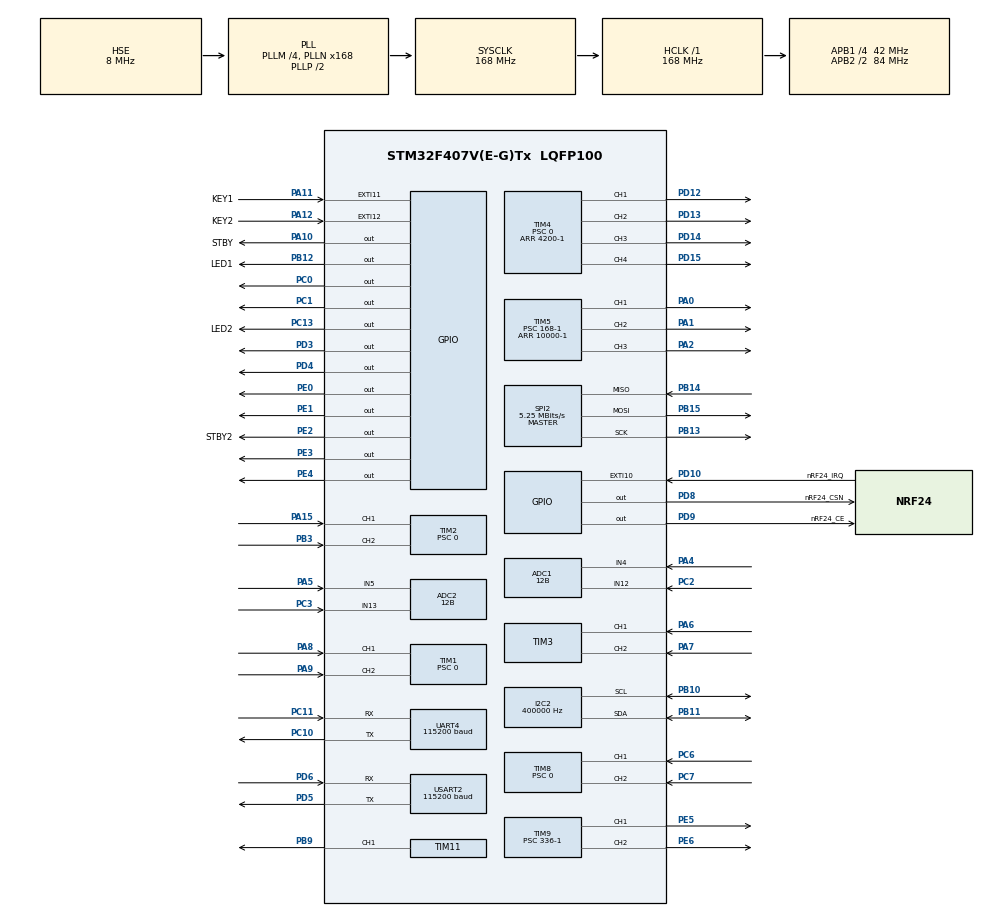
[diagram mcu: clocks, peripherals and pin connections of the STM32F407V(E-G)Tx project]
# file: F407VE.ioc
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ADC1.Channel-0\#ChannelRegularConversion=ADC_CHANNEL_4
ADC1.Channel-1\#ChannelRegularConversion=ADC_CHANNEL_12
ADC1.Channel-IN12=ADC_CHANNEL_12
ADC1.Channel-IN4=ADC_CHANNEL_4
ADC1.ClockPrescaler=ADC_CLOCK_SYNC_PCLK_DIV4
ADC1.ContinuousConvMode=ENABLE
ADC1.DMAContinuousRequests=ENABLE
ADC1.DataAlign=ADC_DATAALIGN_RIGHT
ADC1.DiscontinuousConvMode=DISABLE
ADC1.EOCSelection=ADC_EOC_SINGLE_CONV
ADC1.EnableAnalogWatchDog=false
ADC1.ExternalTrigConv=ADC_SOFTWARE_START
ADC1.ExternalTrigConvEdge=ADC_EXTERNALTRIGCONVEDGE_NONE
ADC1.Mode=ADC_DUALMODE_REGSIMULT
ADC1.NbrOfConversion=2
ADC1.Rank-0\#ChannelRegularConversion=1
ADC1.Rank-1\#ChannelRegularConversion=2
ADC1.Resolution=ADC_RESOLUTION_12B
ADC1.SamplingTime-0\#ChannelRegularConversion=ADC_SAMPLETIME_84CYCLES
ADC1.SamplingTime-1\#ChannelRegularConversion=ADC_SAMPLETIME_84CYCLES
ADC1.ScanConvMode=ENABLE
ADC1.master=1
ADC2.Channel-2\#ChannelRegularConversion=ADC_CHANNEL_5
ADC2.Channel-3\#ChannelRegularConversion=ADC_CHANNEL_13
ADC2.Channel-IN13=ADC_CHANNEL_13
ADC2.Channel-IN5=ADC_CHANNEL_5
ADC2.ClockPrescaler=ADC_CLOCK_SYNC_PCLK_DIV4
ADC2.ContinuousConvMode=ENABLE
ADC2.DMAAccessMode=ADC_DMAACCESSMODE_2
ADC2.DMAContinuousRequests=DISABLE
ADC2.DataAlign=ADC_DATAALIGN_RIGHT
ADC2.DiscontinuousConvMode=DISABLE
ADC2.EOCSelection=ADC_EOC_SINGLE_CONV
ADC2.EnableAnalogWatchDog=false
ADC2.Mode=ADC_DUALMODE_REGSIMULT
ADC2.NbrOfConversion=2
ADC2.Rank-2\#ChannelRegularConversion=1
ADC2.Rank-3\#ChannelRegularConversion=2
ADC2.Resolution=ADC_RESOLUTION_12B
ADC2.SamplingTime-2\#ChannelRegularConversion=ADC_SAMPLETIME_84CYCLES
ADC2.SamplingTime-3\#ChannelRegularConversion=ADC_SAMPLETIME_84CYCLES
ADC2.ScanConvMode=ENABLE
Dma.ADC1.0.Direction=DMA_PERIPH_TO_MEMORY
Dma.ADC1.0.FIFOMode=DMA_FIFOMODE_DISABLE
Dma.ADC1.0.Instance=DMA2_Stream0
Dma.ADC1.0.MemDataAlignment=DMA_MDATAALIGN_WORD
Dma.ADC1.0.MemInc=DMA_MINC_ENABLE
Dma.ADC1.0.Mode=DMA_CIRCULAR
Dma.ADC1.0.PeriphDataAlignment=DMA_PDATAALIGN_WORD
Dma.ADC1.0.PeriphInc=DMA_PINC_DISABLE
Dma.ADC1.0.Priority=DMA_PRIORITY_LOW
Dma.Request0=ADC1
FREERTOS.HEAP_NUMBER=4
FREERTOS.INCLUDE_eTaskGetState=0
FREERTOS.INCLUDE_pcTaskGetTaskName=0
FREERTOS.INCLUDE_uxTaskGetStackHighWaterMark=1
FREERTOS.INCLUDE_uxTaskGetStackHighWaterMark2=0
FREERTOS.INCLUDE_uxTaskPriorityGet=1
FREERTOS.INCLUDE_vTaskCleanUpResources=0
FREERTOS.INCLUDE_vTaskDelay=1
FREERTOS.INCLUDE_vTaskDelayUntil=1
FREERTOS.INCLUDE_vTaskDelete=1
FREERTOS.INCLUDE_vTaskPrioritySet=1
FREERTOS.INCLUDE_vTaskSuspend=1
FREERTOS.INCLUDE_xEventGroupSetBitFromISR=0
FREERTOS.INCLUDE_xQueueGetMutexHolder=0
FREERTOS.INCLUDE_xSemaphoreGetMutexHolder=0
FREERTOS.INCLUDE_xTaskAbortDelay=0
FREERTOS.INCLUDE_xTaskGetCurrentTaskHandle=0
FREERTOS.INCLUDE_xTaskGetHandle=0
FREERTOS.INCLUDE_xTaskResumeFromISR=1
FREERTOS.MEMORY_ALLOCATION=2
FREERTOS.Tasks01=App_Remote_Task,2,512,StartApp_Remote_Task,As weak,NULL,Dynamic,NULL,NULL;App_ChassisTask,1,1024,StartApp_Chassis_Task,As weak,NULL,Dynamic,NULL,NULL;App_Grab_Task,0,768,StartApp_Grab_Task,As weak,NULL,Dynamic,NULL,NULL;App_Sense_Task,-1,512,StartApp_Sense_Task,As weak,NULL,Dynamic,NULL,NULL;App_Daemon_Task,-2,768,StartApp_Daemon_Task,As weak,NULL,Dynamic,NULL,NULL;App_TestBench_T,0,512,StartApp_TestBench_Task,As weak,NULL,Dynamic,NULL,NULL
FREERTOS.configCHECK_FOR_STACK_OVERFLOW=0
FREERTOS.configENABLE_BACKWARD_COMPATIBILITY=1
FREERTOS.configENABLE_FPU=0
FREERTOS.configGENERATE_RUN_TIME_STATS=0
FREERTOS.configIDLE_SHOULD_YIELD=1
FREERTOS.configLIBRARY_LOWEST_INTERRUPT_PRIORITY=15
FREERTOS.configLIBRARY_MAX_SYSCALL_INTERRUPT_PRIORITY=5
FREERTOS.configMAX_CO_ROUTINE_PRIORITIES=2
FREERTOS.configMAX_PRIORITIES=7
FREERTOS.configMAX_TASK_NAME_LEN=16
FREERTOS.configMINIMAL_STACK_SIZE=128
FREERTOS.configQUEUE_REGISTRY_SIZE=8
FREERTOS.configRECORD_STACK_HIGH_ADDRESS=0
FREERTOS.configTICK_RATE_HZ=1000
FREERTOS.configTOTAL_HEAP_SIZE=20480
FREERTOS.configUSE_APPLICATION_TASK_TAG=0
FREERTOS.configUSE_COUNTING_SEMAPHORES=0
FREERTOS.configUSE_CO_ROUTINES=0
FREERTOS.configUSE_DAEMON_TASK_STARTUP_HOOK=0
FREERTOS.configUSE_IDLE_HOOK=0
FREERTOS.configUSE_MALLOC_FAILED_HOOK=0
FREERTOS.configUSE_MUTEXES=1
FREERTOS.configUSE_NEWLIB_REENTRANT=0
FREERTOS.configUSE_POSIX_ERRNO=0
FREERTOS.configUSE_PREEMPTION=1
FREERTOS.configUSE_RECURSIVE_MUTEXES=0
FREERTOS.configUSE_STATS_FORMATTING_FUNCTIONS=0
FREERTOS.configUSE_TASK_NOTIFICATIONS=1
FREERTOS.configUSE_TICKLESS_IDLE=0
FREERTOS.configUSE_TICK_HOOK=0
FREERTOS.configUSE_TIMERS=0
FREERTOS.configUSE_TRACE_FACILITY=0
FREERTOS.copyHeapFile=1
I2C2.AddressingMode=I2C_ADDRESSINGMODE_7BIT
I2C2.ClockSpeed=400000
I2C2.DualAddressMode=I2C_DUALADDRESS_DISABLE
I2C2.DutyCycle=I2C_DUTYCYCLE_2
I2C2.GeneralCallMode=I2C_GENERALCALL_DISABLE
I2C2.I2C_Mode=I2C_Fast
I2C2.NoStretchMode=I2C_NOSTRETCH_DISABLE
I2C2.OwnAddress=0
Mcu.Family=STM32F4
Mcu.Name=STM32F407V(E-G)Tx
Mcu.Package=LQFP100
NVIC.DMA2_Stream0_IRQn=true\:5\:0\:false\:false\:true\:true\:false\:true\:true
NVIC.EXTI15_10_IRQn=true\:5\:0\:false\:false\:true\:true\:true\:true\:true
NVIC.PriorityGroup=NVIC_PRIORITYGROUP_4
NVIC.TIM6_DAC_IRQn=true\:15\:0\:false\:false\:true\:false\:true\:true\:true
NVIC.TimeBase=TIM6_DAC_IRQn
NVIC.TimeBaseIP=TIM6
NVIC.UART4_IRQn=true\:5\:0\:false\:false\:true\:true\:true\:true\:true
NVIC.USART2_IRQn=true\:5\:0\:false\:false\:true\:true\:true\:true\:true
PA0-WKUP.Signal=S_TIM5_CH1
PA1.Signal=S_TIM5_CH2
PA10.GPIO_Label=STBY
PA10.Signal=GPIO_Output
PA11.GPIO_Label=KEY1
PA11.GPIO_ModeDefaultEXTI=GPIO_MODE_IT_FALLING
PA11.GPIO_PuPd=GPIO_PULLUP
PA11.Signal=GPXTI11
PA12.GPIO_Label=KEY2
PA12.GPIO_ModeDefaultEXTI=GPIO_MODE_IT_FALLING
PA12.GPIO_PuPd=GPIO_PULLUP
PA12.Signal=GPXTI12
PA13.Mode=Serial_Wire
PA13.Signal=SYS_JTMS-SWDIO
PA14.Mode=Serial_Wire
PA14.Signal=SYS_JTCK-SWCLK
PA15.Signal=S_TIM2_CH1_ETR
PA2.Signal=S_TIM5_CH3
PA4.Signal=ADCx_IN4
PA5.Signal=ADCx_IN5
PA6.Signal=S_TIM3_CH1
PA7.Signal=S_TIM3_CH2
PA8.Signal=S_TIM1_CH1
PA9.Signal=S_TIM1_CH2
PB10.Mode=I2C
PB10.Signal=I2C2_SCL
PB11.Mode=I2C
PB11.Signal=I2C2_SDA
PB12.GPIO_Label=LED1
PB12.Signal=GPIO_Output
PB13.Mode=Full_Duplex_Master
PB13.Signal=SPI2_SCK
PB14.Mode=Full_Duplex_Master
PB14.Signal=SPI2_MISO
PB15.Mode=Full_Duplex_Master
PB15.Signal=SPI2_MOSI
PB3.Signal=S_TIM2_CH2
PB9.Signal=S_TIM11_CH1
PC0.Signal=GPIO_Output
PC1.Signal=GPIO_Output
PC10.Mode=Asynchronous
PC10.Signal=UART4_TX
PC11.Mode=Asynchronous
PC11.Signal=UART4_RX
PC13-ANTI_TAMP.GPIO_Label=LED2
PC13-ANTI_TAMP.Signal=GPIO_Output
PC14-OSC32_IN.Mode=LSE-External-Oscillator
PC14-OSC32_IN.Signal=RCC_OSC32_IN
PC15-OSC32_OUT.Mode=LSE-External-Oscillator
PC15-OSC32_OUT.Signal=RCC_OSC32_OUT
PC2.Signal=ADCx_IN12
PC3.Signal=ADCx_IN13
PC6.Signal=S_TIM8_CH1
PC7.Signal=S_TIM8_CH2
PD10.GPIO_Label=nRF24_IRQ
PD10.GPIO_ModeDefaultEXTI=GPIO_MODE_IT_FALLING
PD10.GPIO_PuPd=GPIO_PULLUP
PD10.Signal=GPXTI10
PD12.Signal=S_TIM4_CH1
PD13.Signal=S_TIM4_CH2
PD14.Signal=S_TIM4_CH3
PD15.Signal=S_TIM4_CH4
PD3.Signal=GPIO_Output
PD4.Signal=GPIO_Output
PD5.Mode=Asynchronous
PD5.Signal=USART2_TX
PD6.Mode=Asynchronous
PD6.Signal=USART2_RX
PD8.GPIO_Label=nRF24_CSN
PD8.Signal=GPIO_Output
PD9.GPIO_Label=nRF24_CE
PD9.Signal=GPIO_Output
PE0.Signal=GPIO_Output
PE1.Signal=GPIO_Output
PE2.GPIO_Label=STBY2
PE2.Signal=GPIO_Output
PE3.Signal=GPIO_Output
PE4.Signal=GPIO_Output
PE5.Signal=S_TIM9_CH1
PE6.Signal=S_TIM9_CH2
PH0-OSC_IN.Mode=HSE-External-Oscillator
PH0-OSC_IN.Signal=RCC_OSC_IN
PH1-OSC_OUT.Mode=HSE-External-Oscillator
PH1-OSC_OUT.Signal=RCC_OSC_OUT
ProjectManager.HeapSize=0x200
ProjectManager.StackSize=0x400
ProjectManager.TargetToolchain=CMake
RCC.48MHZClocksFreq_Value=84000000
RCC.AHBFreq_Value=168000000
RCC.APB1CLKDivider=RCC_HCLK_DIV4
RCC.APB1Freq_Value=42000000
RCC.APB1TimFreq_Value=84000000
RCC.APB2CLKDivider=RCC_HCLK_DIV2
RCC.APB2Freq_Value=84000000
RCC.APB2TimFreq_Value=168000000
RCC.CortexFreq_Value=168000000
RCC.FLatency=FLASH_LATENCY_5
RCC.HCLKFreq_Value=168000000
RCC.HSE_VALUE=8000000
RCC.HSI_VALUE=16000000
RCC.PLLM=4
RCC.PLLN=168
RCC.PLLSourceVirtual=RCC_PLLSOURCE_HSE
RCC.SYSCLKFreq_VALUE=168000000
RCC.SYSCLKSource=RCC_SYSCLKSOURCE_PLLCLK
RCC.VCOOutputFreq_Value=336000000
SH.ADCx_IN12.0=ADC1_IN12,IN12
SH.ADCx_IN13.0=ADC2_IN13,IN13
SH.ADCx_IN4.0=ADC1_IN4,IN4
SH.ADCx_IN5.0=ADC2_IN5,IN5
SH.S_TIM11_CH1.0=TIM11_CH1,PWM Generation1 CH1
SH.S_TIM1_CH1.0=TIM1_CH1,Encoder_Interface
SH.S_TIM1_CH2.0=TIM1_CH2,Encoder_Interface
SH.S_TIM2_CH1_ETR.0=TIM2_CH1,Encoder_Interface
SH.S_TIM2_CH2.0=TIM2_CH2,Encoder_Interface
SH.S_TIM3_CH1.0=TIM3_CH1,Encoder_Interface
SH.S_TIM3_CH2.0=TIM3_CH2,Encoder_Interface
SH.S_TIM4_CH1.0=TIM4_CH1,PWM Generation1 CH1
SH.S_TIM4_CH2.0=TIM4_CH2,PWM Generation2 CH2
SH.S_TIM4_CH3.0=TIM4_CH3,PWM Generation3 CH3
SH.S_TIM4_CH4.0=TIM4_CH4,PWM Generation4 CH4
SH.S_TIM5_CH1.0=TIM5_CH1,PWM Generation1 CH1
SH.S_TIM5_CH2.0=TIM5_CH2,PWM Generation2 CH2
SH.S_TIM5_CH3.0=TIM5_CH3,PWM Generation3 CH3
SH.S_TIM8_CH1.0=TIM8_CH1,Encoder_Interface
SH.S_TIM8_CH2.0=TIM8_CH2,Encoder_Interface
SH.S_TIM9_CH1.0=TIM9_CH1,PWM Generation1 CH1
SH.S_TIM9_CH2.0=TIM9_CH2,PWM Generation2 CH2
SPI2.BaudRatePrescaler=SPI_BAUDRATEPRESCALER_8
SPI2.CLKPhase=SPI_PHASE_1EDGE
SPI2.CLKPolarity=SPI_POLARITY_LOW
SPI2.CRCCalculation=SPI_CRCCALCULATION_DISABLE
SPI2.CalculateBaudRate=5.25 MBits/s
SPI2.DataSize=SPI_DATASIZE_8BIT
SPI2.Direction=SPI_DIRECTION_2LINES
SPI2.FirstBit=SPI_FIRSTBIT_MSB
SPI2.Mode=SPI_MODE_MASTER
SPI2.NSS=SPI_NSS_SOFT
SPI2.TIMode=SPI_TIMODE_DISABLE
SPI2.VirtualType=VM_MASTER
TIM1.AutoReloadPreload=TIM_AUTORELOAD_PRELOAD_DISABLE
TIM1.ClockDivision=TIM_CLOCKDIVISION_DIV1
TIM1.CounterMode=TIM_COUNTERMODE_UP
TIM1.EncoderMode=TIM_ENCODERMODE_TI12
TIM1.IC1Filter=5
TIM1.IC1Polarity=TIM_ICPOLARITY_RISING
TIM1.IC1Prescaler=TIM_ICPSC_DIV1
TIM1.IC1Selection=TIM_ICSELECTION_DIRECTTI
TIM1.IC2Filter=5
TIM1.IC2Polarity=TIM_ICPOLARITY_RISING
TIM1.IC2Prescaler=TIM_ICPSC_DIV1
TIM1.IC2Selection=TIM_ICSELECTION_DIRECTTI
TIM1.Period=65535
TIM1.Prescaler=0
TIM1.RepetitionCounter=0
TIM1.TIM_MasterOutputTrigger=TIM_TRGO_RESET
TIM1.TIM_MasterSlaveMode=TIM_MASTERSLAVEMODE_DISABLE
TIM10.Channel=TIM_CHANNEL_1
TIM11.Channel=TIM_CHANNEL_1
TIM2.AutoReloadPreload=TIM_AUTORELOAD_PRELOAD_DISABLE
TIM2.ClockDivision=TIM_CLOCKDIVISION_DIV1
TIM2.CounterMode=TIM_COUNTERMODE_UP
TIM2.EncoderMode=TIM_ENCODERMODE_TI12
TIM2.IC1Filter=5
TIM2.IC1Polarity=TIM_ICPOLARITY_RISING
TIM2.IC1Prescaler=TIM_ICPSC_DIV1
TIM2.IC1Selection=TIM_ICSELECTION_DIRECTTI
TIM2.IC2Filter=5
TIM2.IC2Polarity=TIM_ICPOLARITY_RISING
TIM2.IC2Prescaler=TIM_ICPSC_DIV1
TIM2.IC2Selection=TIM_ICSELECTION_DIRECTTI
TIM2.Period=65535
TIM2.Prescaler=0
TIM2.TIM_MasterOutputTrigger=TIM_TRGO_RESET
TIM2.TIM_MasterSlaveMode=TIM_MASTERSLAVEMODE_DISABLE
TIM3.EncoderMode=TIM_ENCODERMODE_TI12
TIM3.IC1Filter=5
TIM3.IC2Filter=5
TIM4.AutoReloadPreload=TIM_AUTORELOAD_PRELOAD_DISABLE
TIM4.Channel-PWM\ Generation1\ CH1=TIM_CHANNEL_1
TIM4.Channel-PWM\ Generation2\ CH2=TIM_CHANNEL_2
TIM4.Channel-PWM\ Generation3\ CH3=TIM_CHANNEL_3
TIM4.Channel-PWM\ Generation4\ CH4=TIM_CHANNEL_4
TIM4.ClockDivision=TIM_CLOCKDIVISION_DIV1
TIM4.CounterMode=TIM_COUNTERMODE_UP
TIM4.OC1Preload_PWM=ENABLE
TIM4.OC2Preload_PWM=ENABLE
TIM4.OC3Preload_PWM=ENABLE
TIM4.OCFastMode_PWM-PWM\ Generation1\ CH1=TIM_OCFAST_DISABLE
TIM4.OCFastMode_PWM-PWM\ Generation2\ CH2=TIM_OCFAST_DISABLE
TIM4.OCFastMode_PWM-PWM\ Generation3\ CH3=TIM_OCFAST_DISABLE
TIM4.OCMode_PWM-PWM\ Generation1\ CH1=TIM_OCMODE_PWM1
TIM4.OCMode_PWM-PWM\ Generation2\ CH2=TIM_OCMODE_PWM1
TIM4.OCMode_PWM-PWM\ Generation3\ CH3=TIM_OCMODE_PWM1
TIM4.OCPolarity_1=TIM_OCPOLARITY_HIGH
TIM4.OCPolarity_2=TIM_OCPOLARITY_HIGH
TIM4.OCPolarity_3=TIM_OCPOLARITY_HIGH
TIM4.Period=4200-1
TIM4.Prescaler=0
TIM4.Pulse-PWM\ Generation1\ CH1=0
TIM4.Pulse-PWM\ Generation2\ CH2=0
TIM4.Pulse-PWM\ Generation3\ CH3=0
TIM4.TIM_MasterOutputTrigger=TIM_TRGO_RESET
TIM4.TIM_MasterSlaveMode=TIM_MASTERSLAVEMODE_DISABLE
TIM5.AutoReloadPreload=TIM_AUTORELOAD_PRELOAD_DISABLE
TIM5.Channel-PWM\ Generation1\ CH1=TIM_CHANNEL_1
TIM5.Channel-PWM\ Generation2\ CH2=TIM_CHANNEL_2
TIM5.Channel-PWM\ Generation3\ CH3=TIM_CHANNEL_3
TIM5.ClockDivision=TIM_CLOCKDIVISION_DIV1
TIM5.CounterMode=TIM_COUNTERMODE_UP
TIM5.OC1Preload_PWM=ENABLE
TIM5.OC2Preload_PWM=ENABLE
TIM5.OC3Preload_PWM=ENABLE
TIM5.OCFastMode_PWM-PWM\ Generation1\ CH1=TIM_OCFAST_DISABLE
TIM5.OCFastMode_PWM-PWM\ Generation2\ CH2=TIM_OCFAST_DISABLE
TIM5.OCFastMode_PWM-PWM\ Generation3\ CH3=TIM_OCFAST_DISABLE
TIM5.OCMode_PWM-PWM\ Generation1\ CH1=TIM_OCMODE_PWM1
TIM5.OCMode_PWM-PWM\ Generation2\ CH2=TIM_OCMODE_PWM1
TIM5.OCMode_PWM-PWM\ Generation3\ CH3=TIM_OCMODE_PWM1
TIM5.OCPolarity_1=TIM_OCPOLARITY_HIGH
TIM5.OCPolarity_2=TIM_OCPOLARITY_HIGH
TIM5.OCPolarity_3=TIM_OCPOLARITY_HIGH
TIM5.Period=10000-1
TIM5.Prescaler=168-1
TIM5.Pulse-PWM\ Generation1\ CH1=0
TIM5.Pulse-PWM\ Generation2\ CH2=0
TIM5.Pulse-PWM\ Generation3\ CH3=0
TIM5.TIM_MasterOutputTrigger=TIM_TRGO_RESET
TIM5.TIM_MasterSlaveMode=TIM_MASTERSLAVEMODE_DISABLE
TIM8.AutoReloadPreload=TIM_AUTORELOAD_PRELOAD_DISABLE
TIM8.ClockDivision=TIM_CLOCKDIVISION_DIV1
TIM8.CounterMode=TIM_COUNTERMODE_UP
TIM8.EncoderMode=TIM_ENCODERMODE_TI12
TIM8.IC1Filter=5
TIM8.IC1Polarity=TIM_ICPOLARITY_RISING
TIM8.IC1Prescaler=TIM_ICPSC_DIV1
TIM8.IC1Selection=TIM_ICSELECTION_DIRECTTI
TIM8.IC2Filter=5
TIM8.IC2Polarity=TIM_ICPOLARITY_RISING
TIM8.IC2Prescaler=TIM_ICPSC_DIV1
TIM8.IC2Selection=TIM_ICSELECTION_DIRECTTI
TIM8.Period=65535
TIM8.Prescaler=0
TIM8.RepetitionCounter=0
TIM8.TIM_MasterOutputTrigger=TIM_TRGO_RESET
TIM8.TIM_MasterSlaveMode=TIM_MASTERSLAVEMODE_DISABLE
TIM9.AutoReloadPreload=TIM_AUTORELOAD_PRELOAD_DISABLE
TIM9.Channel-PWM\ Generation1\ CH1=TIM_CHANNEL_1
TIM9.Channel-PWM\ Generation2\ CH2=TIM_CHANNEL_2
TIM9.ClockDivision=TIM_CLOCKDIVISION_DIV1
TIM9.CounterMode=TIM_COUNTERMODE_UP
TIM9.OC1Preload_PWM=ENABLE
TIM9.OC2Preload_PWM=ENABLE
TIM9.OCFastMode_PWM-PWM\ Generation1\ CH1=TIM_OCFAST_DISABLE
TIM9.OCFastMode_PWM-PWM\ Generation2\ CH2=TIM_OCFAST_DISABLE
TIM9.OCMode_PWM-PWM\ Generation1\ CH1=TIM_OCMODE_PWM1
TIM9.OCMode_PWM-PWM\ Generation2\ CH2=TIM_OCMODE_PWM1
TIM9.OCPolarity_1=TIM_OCPOLARITY_HIGH
TIM9.OCPolarity_2=TIM_OCPOLARITY_HIGH
TIM9.Period=2000-1
TIM9.Prescaler=336-1
TIM9.Pulse-PWM\ Generation1\ CH1=0
TIM9.Pulse-PWM\ Generation2\ CH2=0
UART4.BaudRate=115200
UART4.Mode=MODE_TX_RX
UART4.OverSampling=UART_OVERSAMPLING_16
UART4.Parity=PARITY_NONE
UART4.StopBits=UART_STOPBITS_1
UART4.VirtualMode=Asynchronous
UART4.WordLength=WORDLENGTH_8B
USART2.BaudRate=115200
USART2.Mode=MODE_TX_RX
USART2.OverSampling=UART_OVERSAMPLING_16
USART2.Parity=PARITY_NONE
USART2.StopBits=STOPBITS_1
USART2.VirtualMode=VM_ASYNC
USART2.WordLength=WORDLENGTH_8B
VP_FREERTOS_VS_CMSIS_V1.Mode=CMSIS_V1
VP_SYS_VS_tim6.Mode=TIM6
VP_TIM10_VS_ClockSourceINT.Mode=Enable_Timer
VP_TIM11_VS_ClockSourceINT.Mode=Enable_Timer
VP_TIM4_VS_ClockSourceINT.Mode=Internal
VP_TIM5_VS_ClockSourceINT.Mode=Internal
VP_TIM9_VS_ClockSourceINT.Mode=Internal
board=custom

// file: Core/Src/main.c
/* USER CODE BEGIN Header */
/**
  ******************************************************************************
  * @file           : main.c
  * @brief          : Main program body
  ******************************************************************************
  * @attention
  *
  * Copyright (c) 2026 STMicroelectronics.
  * All rights reserved.
  *
  * This software is licensed under terms that can be found in the LICENSE file
  * in the root directory of this software component.
  * If no LICENSE file comes with this software, it is provided AS-IS.
  *
  ******************************************************************************
  */
/* USER CODE END Header */
#include "main.h"
#include "cmsis_os.h"
#include "adc.h"
#include "dma.h"
#include "i2c.h"
#include "spi.h"
#include "tim.h"
#include "usart.h"
#include "gpio.h"

/* USER CODE BEGIN Includes */
#include "bsp_sys.h"
#include "bsp_log.h"
#include "bsp_encoder.h"
#include "bsp_pwm.h"
#include "bsp_adc.h"
#include "bsp_iic.h"
/* USER CODE END Includes */

void SystemClock_Config(void);
void MX_FREERTOS_Init(void);

int main(void)
{

  /* MCU Configuration--------------------------------------------------------*/

  /* Reset of all peripherals, Initializes the Flash interface and the Systick. */
  HAL_Init();

  /* Configure the system clock */
  SystemClock_Config();

  /* Initialize all configured peripherals */
  MX_GPIO_Init();
  MX_DMA_Init();
  MX_ADC1_Init();
  MX_ADC2_Init();
  MX_I2C2_Init();
  MX_SPI2_Init();
  MX_TIM1_Init();
  MX_TIM2_Init();
  MX_TIM3_Init();
  MX_TIM4_Init();
  MX_TIM5_Init();
  MX_TIM8_Init();
  MX_UART4_Init();
  MX_TIM9_Init();
  MX_USART2_UART_Init();
  MX_TIM10_Init();
  MX_TIM11_Init();
  /* USER CODE BEGIN 2 */
  /* ADC方案B: 双同步+连续转换+DMA循环由硬件自动搬运, 不需要DMA中断.
   * CubeMX 在双同步模式下强制使能 DMA2_Stream0 中断(界面置灰不可关),
   * 在此显式屏蔽, 避免循环模式下半满/全满中断频繁打断RTOS任务. */
  HAL_NVIC_DisableIRQ(DMA2_Stream0_IRQn);
  /* S0: BSP 初始化（时钟自检 + DWT）与日志口启动（UART4 已在上面 MX 初始化） */
  Bsp_Init();
  Log_Init();
  /* S3: 启动四路编码器计数（MX_TIMx_Init 的编码器配置已在上面完成） */
  Encoder_InitAll();
  /* S4: 启动 9 路 PWM 输出（20K×4 + 250Hz×2 + 50Hz×3，compare 保持
   * CubeMX Pulse=0：duty 0 / 不发脉冲） */
  Pwm_InitAll();
  /* S6: 启动 ADC1/2 双同步双 rank DMA 循环采样（V/I + J0/J1，丢前2轮） */
  Adc_Init();
  /* S7: I²C2 总线服务就绪（校验 hi2c2；阻塞读写+超时+总线恢复见 Iic_*） */
  Iic_Init();
  /* USER CODE END 2 */

  /* Call init function for freertos objects (in cmsis_os2.c) */
  MX_FREERTOS_Init();

  /* Start scheduler */
  osKernelStart();

  /* We should never get here as control is now taken by the scheduler */

  /* Infinite loop */
  while (1)
  {

  }
}

void SystemClock_Config(void)
{
  RCC_OscInitTypeDef RCC_OscInitStruct = {0};
  RCC_ClkInitTypeDef RCC_ClkInitStruct = {0};

  /** Configure the main internal regulator output voltage
  */
  __HAL_RCC_PWR_CLK_ENABLE();
  __HAL_PWR_VOLTAGESCALING_CONFIG(PWR_REGULATOR_VOLTAGE_SCALE1);

  /** Initializes the RCC Oscillators according to the specified parameters
  * in the RCC_OscInitTypeDef structure.
  */
  RCC_OscInitStruct.OscillatorType = RCC_OSCILLATORTYPE_HSE;
  RCC_OscInitStruct.HSEState = RCC_HSE_ON;
  RCC_OscInitStruct.PLL.PLLState = RCC_PLL_ON;
  RCC_OscInitStruct.PLL.PLLSource = RCC_PLLSOURCE_HSE;
  RCC_OscInitStruct.PLL.PLLM = 4;
  RCC_OscInitStruct.PLL.PLLN = 168;
  RCC_OscInitStruct.PLL.PLLP = RCC_PLLP_DIV2;
  RCC_OscInitStruct.PLL.PLLQ = 4;
  if (HAL_RCC_OscConfig(&RCC_OscInitStruct) != HAL_OK)
  {
    Error_Handler();
  }

  /** Initializes the CPU, AHB and APB buses clocks
  */
  RCC_ClkInitStruct.ClockType = RCC_CLOCKTYPE_HCLK|RCC_CLOCKTYPE_SYSCLK
                              |RCC_CLOCKTYPE_PCLK1|RCC_CLOCKTYPE_PCLK2;
  RCC_ClkInitStruct.SYSCLKSource = RCC_SYSCLKSOURCE_PLLCLK;
  RCC_ClkInitStruct.AHBCLKDivider = RCC_SYSCLK_DIV1;
  RCC_ClkInitStruct.APB1CLKDivider = RCC_HCLK_DIV4;
  RCC_ClkInitStruct.APB2CLKDivider = RCC_HCLK_DIV2;

  if (HAL_RCC_ClockConfig(&RCC_ClkInitStruct, FLASH_LATENCY_5) != HAL_OK)
  {
    Error_Handler();
  }
}

void HAL_TIM_PeriodElapsedCallback(TIM_HandleTypeDef *htim)
{
  if (htim->Instance == TIM6)
  {
    HAL_IncTick();
  }
}

void Error_Handler(void)
{
  __disable_irq();
  while (1)
  {
  }
}

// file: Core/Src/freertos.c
/* USER CODE BEGIN Header */
/**
  ******************************************************************************
  * File Name          : freertos.c
  * Description        : Code for freertos applications
  ******************************************************************************
  * @attention
  *
  * Copyright (c) 2026 STMicroelectronics.
  * All rights reserved.
  *
  * This software is licensed under terms that can be found in the LICENSE file
  * in the root directory of this software component.
  * If no LICENSE file comes with this software, it is provided AS-IS.
  *
  ******************************************************************************
  */
/* USER CODE END Header */

#include "FreeRTOS.h"
#include "task.h"
#include "main.h"
#include "cmsis_os.h"

osThreadId App_Remote_TaskHandle;
osThreadId App_ChassisTaskHandle;
osThreadId App_Grab_TaskHandle;
osThreadId App_Sense_TaskHandle;
osThreadId App_Daemon_TaskHandle;
osThreadId App_TestBench_THandle;

void StartApp_Remote_Task(void const * argument);
void StartApp_Chassis_Task(void const * argument);
void StartApp_Grab_Task(void const * argument);
void StartApp_Sense_Task(void const * argument);
void StartApp_Daemon_Task(void const * argument);
void StartApp_TestBench_Task(void const * argument);

void MX_FREERTOS_Init(void); /* (MISRA C 2004 rule 8.1) */

/* GetIdleTaskMemory prototype (linked to static allocation support) */
void vApplicationGetIdleTaskMemory( StaticTask_t **ppxIdleTaskTCBBuffer, StackType_t **ppxIdleTaskStackBuffer, uint32_t *pulIdleTaskStackSize );

/* USER CODE BEGIN GET_IDLE_TASK_MEMORY */
static StaticTask_t xIdleTaskTCBBuffer;
static StackType_t xIdleStack[configMINIMAL_STACK_SIZE];

void vApplicationGetIdleTaskMemory( StaticTask_t **ppxIdleTaskTCBBuffer, StackType_t **ppxIdleTaskStackBuffer, uint32_t *pulIdleTaskStackSize )
{
  *ppxIdleTaskTCBBuffer = &xIdleTaskTCBBuffer;
  *ppxIdleTaskStackBuffer = &xIdleStack[0];
  *pulIdleTaskStackSize = configMINIMAL_STACK_SIZE;
  /* place for user code */
}
/* USER CODE END GET_IDLE_TASK_MEMORY */

void MX_FREERTOS_Init(void) {

  /* Create the thread(s) */
  /* definition and creation of App_Remote_Task */
  osThreadDef(App_Remote_Task, StartApp_Remote_Task, osPriorityHigh, 0, 512);
  App_Remote_TaskHandle = osThreadCreate(osThread(App_Remote_Task), NULL);

  /* definition and creation of App_ChassisTask */
  osThreadDef(App_ChassisTask, StartApp_Chassis_Task, osPriorityAboveNormal, 0, 1024);
  App_ChassisTaskHandle = osThreadCreate(osThread(App_ChassisTask), NULL);

  /* definition and creation of App_Grab_Task */
  osThreadDef(App_Grab_Task, StartApp_Grab_Task, osPriorityNormal, 0, 768);
  App_Grab_TaskHandle = osThreadCreate(osThread(App_Grab_Task), NULL);

  /* definition and creation of App_Sense_Task */
  osThreadDef(App_Sense_Task, StartApp_Sense_Task, osPriorityBelowNormal, 0, 512);
  App_Sense_TaskHandle = osThreadCreate(osThread(App_Sense_Task), NULL);

  /* definition and creation of App_Daemon_Task */
  osThreadDef(App_Daemon_Task, StartApp_Daemon_Task, osPriorityLow, 0, 768);
  App_Daemon_TaskHandle = osThreadCreate(osThread(App_Daemon_Task), NULL);

  /* definition and creation of App_TestBench_T */
  osThreadDef(App_TestBench_T, StartApp_TestBench_Task, osPriorityNormal, 0, 512);
  App_TestBench_THandle = osThreadCreate(osThread(App_TestBench_T), NULL);

}

__weak void StartApp_Remote_Task(void const * argument)
{
  for(;;)
  {
    osDelay(1);
  }
}

__weak void StartApp_Chassis_Task(void const * argument)
{
  for(;;)
  {
    osDelay(1);
  }
}

__weak void StartApp_Grab_Task(void const * argument)
{
  for(;;)
  {
    osDelay(1);
  }
}

__weak void StartApp_Sense_Task(void const * argument)
{
  for(;;)
  {
    osDelay(1);
  }
}

__weak void StartApp_Daemon_Task(void const * argument)
{
  for(;;)
  {
    osDelay(1);
  }
}

__weak void StartApp_TestBench_Task(void const * argument)
{
  for(;;)
  {
    osDelay(1);
  }
}
